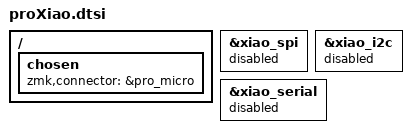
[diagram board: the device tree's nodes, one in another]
/*
 * Copyright (c) 2020 The ZMK Contributors
 *
 * SPDX-License-Identifier: MIT
 */

#include <dt-bindings/zmk/matrix_transform.h>
#include "arduino_pro_micro_pins.dtsi"


/ {
	chosen {
        zmk,connector = &pro_micro;
	};

};
&xiao_spi { status = "disabled"; };
&xiao_i2c { status = "disabled"; };
&xiao_serial { status = "disabled"; };
